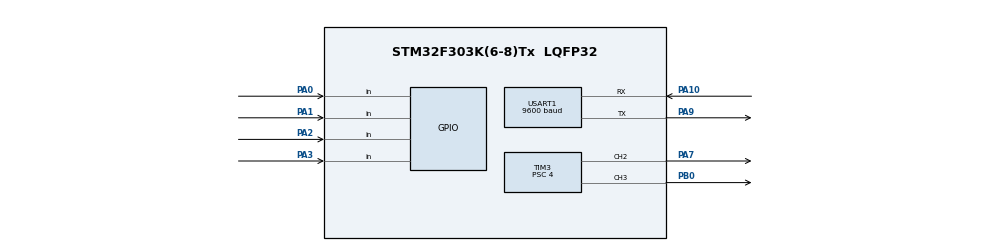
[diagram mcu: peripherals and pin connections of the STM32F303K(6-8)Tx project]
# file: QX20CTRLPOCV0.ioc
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Mcu.Family=STM32F3
Mcu.Name=STM32F303K(6-8)Tx
Mcu.Package=LQFP32
NVIC.PriorityGroup=NVIC_PRIORITYGROUP_4
PA0.GPIO_PuPd=GPIO_PULLUP
PA0.Signal=GPIO_Input
PA1.GPIO_PuPd=GPIO_PULLUP
PA1.Signal=GPIO_Input
PA10.Mode=Asynchronous
PA10.Signal=USART1_RX
PA2.GPIO_PuPd=GPIO_PULLUP
PA2.Signal=GPIO_Input
PA3.GPIO_PuPd=GPIO_PULLUP
PA3.Signal=GPIO_Input
PA7.Signal=S_TIM3_CH2
PA9.Mode=Asynchronous
PA9.Signal=USART1_TX
PB0.Signal=S_TIM3_CH3
ProjectManager.HeapSize=0x200
ProjectManager.StackSize=0x400
ProjectManager.TargetToolchain=Makefile
RCC.AHBFreq_Value=36000000
RCC.APB1Freq_Value=36000000
RCC.APB1TimFreq_Value=36000000
RCC.APB2Freq_Value=36000000
RCC.APB2TimFreq_Value=36000000
RCC.CortexFreq_Value=36000000
RCC.HCLKFreq_Value=36000000
RCC.HSE_VALUE=8000000
RCC.HSI_VALUE=8000000
RCC.PLLMUL=RCC_PLL_MUL9
RCC.SYSCLKFreq_VALUE=36000000
RCC.SYSCLKSourceVirtual=RCC_SYSCLKSOURCE_PLLCLK
SH.S_TIM3_CH2.0=TIM3_CH2,PWM Generation2 CH2
SH.S_TIM3_CH3.0=TIM3_CH3,PWM Generation3 CH3
TIM3.Channel-PWM\ Generation2\ CH2=TIM_CHANNEL_2
TIM3.Channel-PWM\ Generation3\ CH3=TIM_CHANNEL_3
TIM3.Prescaler=4
TIM3.Pulse-PWM\ Generation2\ CH2=13500
TIM3.Pulse-PWM\ Generation3\ CH3=13500
USART1.BaudRate=9600
USART1.VirtualMode-Asynchronous=VM_ASYNC
VP_TIM3_VS_ClockSourceINT.Mode=Internal
board=custom

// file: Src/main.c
/* USER CODE BEGIN Header */
/**
  ******************************************************************************
  * @file           : main.c
  * @brief          : Main program body
  ******************************************************************************
  * @attention
  *
  * <h2><center>&copy; Copyright (c) 2019 STMicroelectronics.
  * All rights reserved.</center></h2>
  *
  * This software component is licensed by ST under BSD 3-Clause license,
  * the "License"; You may not use this file except in compliance with the
  * License. You may obtain a copy of the License at:
  *                        opensource.org/licenses/BSD-3-Clause
  *
  ******************************************************************************
  */
/* USER CODE END Header */

#include "main.h"
#include "QX20.h"

void SystemClock_Config(void);
static void MX_GPIO_Init(void);
static void MX_TIM3_Init(void);
static void MX_USART1_UART_Init(void);

int tick = 1;
/*
rudDegState rudder;
elvDegState elevator;
*/
void tickPlus(){
  tick++;
}

int main(void)
{
  LL_APB2_GRP1_EnableClock(LL_APB2_GRP1_PERIPH_SYSCFG);
  LL_APB1_GRP1_EnableClock(LL_APB1_GRP1_PERIPH_PWR);

  NVIC_SetPriorityGrouping(NVIC_PRIORITYGROUP_4);
  SystemClock_Config();
  MX_GPIO_Init();
  MX_TIM3_Init();
  MX_USART1_UART_Init();

  TIM3->CCR2 = ELV_N;
  TIM3->CCR3 = RUD_N;
  while (1) {
    if(tick % 10 ==  0){
      if (!(GPIOA->IDR & 0x0001)) {//0000 0001 up
        TIM3->CCR2 = ELV_U;
      } else if (!(GPIOA->IDR & 0x0002)) {//0000 0010 down
        TIM3->CCR2 = ELV_D;
      } else {
        TIM3->CCR2 = ELV_N;
      }

      if (!(GPIOA->IDR & 0x0004)) {//0000 0100 left
        TIM3->CCR3 = RUD_L;
      } else if (!(GPIOA->IDR & 0x0008)) {//0000 1000 right
        TIM3->CCR3 = RUD_R;
      }else{
        TIM3->CCR3 = RUD_N;
      }
    }
    /*
    //角度出し用
    if(tick%500 == 0){

      if (!(GPIOA->IDR & 0x0001)) {//0000 0001 up
        elevator.N += 500;
      }
      if (!(GPIOA->IDR & 0x0002)) {//0000 0010 down
        elevator.N -= 500;
      }
      if (!(GPIOA->IDR & 0x0004)) {//0000 0100 left
        elevator.N -= 50;
      }
      if (!(GPIOA->IDR & 0x0008)) {//0000 1000 right
        elevator.N += 50;
      }
      TIM3->CCR2 = elevator.N;
      TIM3->CCR3 = rudder.N;

      LL_USART_TransmitData9(USART1, (char)((elevator.N/10000)+'0'));
      while (!LL_USART_IsActiveFlag_TXE(USART1));
      LL_USART_TransmitData9(USART1, (char)((elevator.N%10000/1000)+'0'));
      while (!LL_USART_IsActiveFlag_TXE(USART1));
      LL_USART_TransmitData9(USART1, (char)((elevator.N%1000/100)+'0'));
      while (!LL_USART_IsActiveFlag_TXE(USART1));
      LL_USART_TransmitData9(USART1, (char)((elevator.N%100/10)+'0'));
      while (!LL_USART_IsActiveFlag_TXE(USART1));
      LL_USART_TransmitData9(USART1, (char)((elevator.N%10)+'0'));
      while (!LL_USART_IsActiveFlag_TXE(USART1));
      LL_USART_TransmitData9(USART1, '\n');
      while (!LL_USART_IsActiveFlag_TXE(USART1));
	  }
    */
  }
  /* USER CODE END 3 */
}

void SystemClock_Config(void)
{
  LL_FLASH_SetLatency(LL_FLASH_LATENCY_1);

  if(LL_FLASH_GetLatency() != LL_FLASH_LATENCY_1)
  {
  Error_Handler();
  }
  LL_RCC_HSI_Enable();

   /* Wait till HSI is ready */
  while(LL_RCC_HSI_IsReady() != 1)
  {

  }
  LL_RCC_HSI_SetCalibTrimming(16);
  LL_RCC_PLL_ConfigDomain_SYS(LL_RCC_PLLSOURCE_HSI_DIV_2, LL_RCC_PLL_MUL_9);
  LL_RCC_PLL_Enable();

   /* Wait till PLL is ready */
  while(LL_RCC_PLL_IsReady() != 1)
  {

  }
  LL_RCC_SetAHBPrescaler(LL_RCC_SYSCLK_DIV_1);
  LL_RCC_SetAPB1Prescaler(LL_RCC_APB1_DIV_1);
  LL_RCC_SetAPB2Prescaler(LL_RCC_APB1_DIV_1);
  LL_RCC_SetSysClkSource(LL_RCC_SYS_CLKSOURCE_PLL);

   /* Wait till System clock is ready */
  while(LL_RCC_GetSysClkSource() != LL_RCC_SYS_CLKSOURCE_STATUS_PLL)
  {

  }
  LL_Init1msTick(36000000);
  LL_SYSTICK_SetClkSource(LL_SYSTICK_CLKSOURCE_HCLK);
  LL_SetSystemCoreClock(36000000);
  LL_RCC_SetUSARTClockSource(LL_RCC_USART1_CLKSOURCE_PCLK1);
  LL_SYSTICK_EnableIT();
}

static void MX_TIM3_Init(void)
{

  LL_TIM_InitTypeDef TIM_InitStruct = {0};
  LL_TIM_OC_InitTypeDef TIM_OC_InitStruct = {0};

  LL_GPIO_InitTypeDef GPIO_InitStruct = {0};

  /* Peripheral clock enable */
  LL_APB1_GRP1_EnableClock(LL_APB1_GRP1_PERIPH_TIM3);

  TIM_InitStruct.Prescaler = 1;
  TIM_InitStruct.CounterMode = LL_TIM_COUNTERMODE_UP;
  TIM_InitStruct.Autoreload = 54000;
  TIM_InitStruct.ClockDivision = LL_TIM_CLOCKDIVISION_DIV1;
  LL_TIM_Init(TIM3, &TIM_InitStruct);
  LL_TIM_EnableARRPreload(TIM3);
  LL_TIM_SetClockSource(TIM3, LL_TIM_CLOCKSOURCE_INTERNAL);
  LL_TIM_OC_EnablePreload(TIM3, LL_TIM_CHANNEL_CH2);
  TIM_OC_InitStruct.OCMode = LL_TIM_OCMODE_PWM1;
  TIM_OC_InitStruct.OCState = LL_TIM_OCSTATE_ENABLE;
  TIM_OC_InitStruct.OCNState = LL_TIM_OCSTATE_DISABLE;
  TIM_OC_InitStruct.CompareValue = 1500;
  TIM_OC_InitStruct.OCPolarity = LL_TIM_OCPOLARITY_HIGH;
  LL_TIM_OC_Init(TIM3, LL_TIM_CHANNEL_CH2, &TIM_OC_InitStruct);
  LL_TIM_OC_DisableFast(TIM3, LL_TIM_CHANNEL_CH2);
  LL_TIM_OC_EnablePreload(TIM3, LL_TIM_CHANNEL_CH3);
  TIM_OC_InitStruct.OCState = LL_TIM_OCSTATE_ENABLE;
  TIM_OC_InitStruct.OCNState = LL_TIM_OCSTATE_DISABLE;
  LL_TIM_OC_Init(TIM3, LL_TIM_CHANNEL_CH3, &TIM_OC_InitStruct);
  LL_TIM_OC_DisableFast(TIM3, LL_TIM_CHANNEL_CH3);
  LL_TIM_SetTriggerOutput(TIM3, LL_TIM_TRGO_RESET);
  LL_TIM_DisableMasterSlaveMode(TIM3);
  /* USER CODE BEGIN TIM3_Init 2 */
  LL_TIM_EnableCounter(TIM3);
  LL_TIM_EnableAllOutputs(TIM3);
  /* USER CODE END TIM3_Init 2 */
  LL_AHB1_GRP1_EnableClock(LL_AHB1_GRP1_PERIPH_GPIOA);
  LL_AHB1_GRP1_EnableClock(LL_AHB1_GRP1_PERIPH_GPIOB);
  /**TIM3 GPIO Configuration
  PA7   ------> TIM3_CH2
  PB0   ------> TIM3_CH3
  */
  GPIO_InitStruct.Pin = LL_GPIO_PIN_7;
  GPIO_InitStruct.Mode = LL_GPIO_MODE_ALTERNATE;
  GPIO_InitStruct.Speed = LL_GPIO_SPEED_FREQ_LOW;
  GPIO_InitStruct.OutputType = LL_GPIO_OUTPUT_PUSHPULL;
  GPIO_InitStruct.Pull = LL_GPIO_PULL_NO;
  GPIO_InitStruct.Alternate = LL_GPIO_AF_2;
  LL_GPIO_Init(GPIOA, &GPIO_InitStruct);

  GPIO_InitStruct.Pin = LL_GPIO_PIN_0;
  GPIO_InitStruct.Mode = LL_GPIO_MODE_ALTERNATE;
  GPIO_InitStruct.Speed = LL_GPIO_SPEED_FREQ_LOW;
  GPIO_InitStruct.OutputType = LL_GPIO_OUTPUT_PUSHPULL;
  GPIO_InitStruct.Pull = LL_GPIO_PULL_NO;
  GPIO_InitStruct.Alternate = LL_GPIO_AF_2;
  LL_GPIO_Init(GPIOB, &GPIO_InitStruct);

}

static void MX_USART1_UART_Init(void)
{

  LL_USART_InitTypeDef USART_InitStruct = {0};

  LL_GPIO_InitTypeDef GPIO_InitStruct = {0};

  /* Peripheral clock enable */
  LL_APB2_GRP1_EnableClock(LL_APB2_GRP1_PERIPH_USART1);

  LL_AHB1_GRP1_EnableClock(LL_AHB1_GRP1_PERIPH_GPIOA);
  /**USART1 GPIO Configuration
  PA9   ------> USART1_TX
  PA10   ------> USART1_RX
  */
  GPIO_InitStruct.Pin = LL_GPIO_PIN_9|LL_GPIO_PIN_10;
  GPIO_InitStruct.Mode = LL_GPIO_MODE_ALTERNATE;
  GPIO_InitStruct.Speed = LL_GPIO_SPEED_FREQ_HIGH;
  GPIO_InitStruct.OutputType = LL_GPIO_OUTPUT_PUSHPULL;
  GPIO_InitStruct.Pull = LL_GPIO_PULL_NO;
  GPIO_InitStruct.Alternate = LL_GPIO_AF_7;
  LL_GPIO_Init(GPIOA, &GPIO_InitStruct);

  USART_InitStruct.BaudRate = 9600;
  USART_InitStruct.DataWidth = LL_USART_DATAWIDTH_8B;
  USART_InitStruct.StopBits = LL_USART_STOPBITS_1;
  USART_InitStruct.Parity = LL_USART_PARITY_NONE;
  USART_InitStruct.TransferDirection = LL_USART_DIRECTION_TX_RX;
  USART_InitStruct.HardwareFlowControl = LL_USART_HWCONTROL_NONE;
  USART_InitStruct.OverSampling = LL_USART_OVERSAMPLING_16;
  LL_USART_Init(USART1, &USART_InitStruct);
  LL_USART_DisableIT_CTS(USART1);
  LL_USART_ConfigAsyncMode(USART1);
  LL_USART_Enable(USART1);

}

static void MX_GPIO_Init(void)
{
  LL_GPIO_InitTypeDef GPIO_InitStruct = {0};

  /* GPIO Ports Clock Enable */
  LL_AHB1_GRP1_EnableClock(LL_AHB1_GRP1_PERIPH_GPIOA);
  LL_AHB1_GRP1_EnableClock(LL_AHB1_GRP1_PERIPH_GPIOB);

  /**/
  GPIO_InitStruct.Pin = LL_GPIO_PIN_0|LL_GPIO_PIN_1|LL_GPIO_PIN_2|LL_GPIO_PIN_3;
  GPIO_InitStruct.Mode = LL_GPIO_MODE_INPUT;
  GPIO_InitStruct.Pull = LL_GPIO_PULL_UP;
  LL_GPIO_Init(GPIOA, &GPIO_InitStruct);

}

void Error_Handler(void)
{
}

/************************ (C) COPYRIGHT STMicroelectronics *****END OF FILE****/
